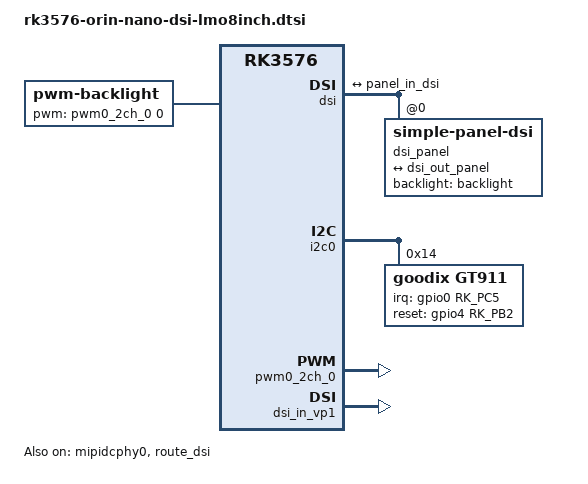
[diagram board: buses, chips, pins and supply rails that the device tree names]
// SPDX-License-Identifier: (GPL-2.0+ OR MIT)
/*
 * Guangzhou Easy EAl Technology Co., Ltd.
 *
 */

/{
	backlight: backlight {
		status = "okay";
		compatible = "pwm-backlight";
		pwms = <&pwm0_2ch_0 0 25000 0>;
		brightness-levels = <
			  0  20  20  21  21  22  22  23
			 23  24  24  25  25  26  26  27
			 27  28  28  29  29  30  30  31
			 31  32  32  33  33  34  34  35
			 35  36  36  37  37  38  38  39
			 40  41  42  43  44  45  46  47
			 48  49  50  51  52  53  54  55
			 56  57  58  59  60  61  62  63
			 64  65  66  67  68  69  70  71
			 72  73  74  75  76  77  78  79
			 80  81  82  83  84  85  86  87
			 88  89  90  91  92  93  94  95
			 96  97  98  99 100 101 102 103
			104 105 106 107 108 109 110 111
			112 113 114 115 116 117 118 119
			120 121 122 123 124 125 126 127
			128 129 130 131 132 133 134 135
			136 137 138 139 140 141 142 143
			144 145 146 147 148 149 150 151
			152 153 154 155 156 157 158 159
			160 161 162 163 164 165 166 167
			168 169 170 171 172 173 174 175
			176 177 178 179 180 181 182 183
			184 185 186 187 188 189 190 191
			192 193 194 195 196 197 198 199
			200 201 202 203 204 205 206 207
			208 209 210 211 212 213 214 215
			216 217 218 219 220 221 222 223
			224 225 226 227 228 229 230 231
			232 233 234 235 236 237 238 239
			240 241 242 243 244 245 246 247
			248 249 250 251 252 253 254 255
		>;
		default-brightness-level = <255>;
	};
};

&dsi {
	status = "okay";
	//rockchip,lane-rate = <1000>;
	dsi_panel: panel@0 {
		pinctrl-names = "default";
		pinctrl-0 = <&lcd_rst_gpio>;
		status = "okay";
		compatible = "simple-panel-dsi";
		reg = <0>;
		backlight = <&backlight>;
		dsi,flags = <(MIPI_DSI_MODE_VIDEO | MIPI_DSI_MODE_VIDEO_BURST |
			      MIPI_DSI_MODE_LPM | MIPI_DSI_MODE_NO_EOT_PACKET)>;
		dsi,format = <MIPI_DSI_FMT_RGB888>;
		dsi,lanes  = <4>;
		panel-init-sequence = [
			39 00 04 FF 98 81 03
			15 00 02 01 00
			15 00 02 02 00
			15 00 02 03 73
			15 00 02 04 00
			15 00 02 05 00
			15 00 02 06 08
			15 00 02 07 00
			15 00 02 08 00
			15 00 02 09 00
			15 00 02 0A 01
			15 00 02 0B 01
			15 00 02 0C 00
			15 00 02 0D 01
			15 00 02 0E 01
			15 00 02 0F 00
			15 00 02 10 00
			15 00 02 11 00
			15 00 02 12 00
			15 00 02 13 1F
			15 00 02 14 1F
			15 00 02 15 00
			15 00 02 16 00
			15 00 02 17 00
			15 00 02 18 00
			15 00 02 19 00
			15 00 02 1A 00
			15 00 02 1B 00
			15 00 02 1C 00
			15 00 02 1D 00
			15 00 02 1E 40
			15 00 02 1F C0
			15 00 02 20 06
			15 00 02 21 01
			15 00 02 22 06
			15 00 02 23 01
			15 00 02 24 88
			15 00 02 25 88
			15 00 02 26 00
			15 00 02 27 00
			15 00 02 28 3B
			15 00 02 29 03
			15 00 02 2A 00
			15 00 02 2B 00
			15 00 02 2C 00
			15 00 02 2D 00
			15 00 02 2E 00
			15 00 02 2F 00
			15 00 02 30 00
			15 00 02 31 00
			15 00 02 32 00
			15 00 02 33 00
			15 00 02 34 00
			15 00 02 35 00
			15 00 02 36 00
			15 00 02 37 00
			15 00 02 38 00
			15 00 02 39 00
			15 00 02 3A 00
			15 00 02 3B 00
			15 00 02 3C 00
			15 00 02 3D 00
			15 00 02 3E 00
			15 00 02 3F 00
			15 00 02 40 00
			15 00 02 41 00
			15 00 02 42 00
			15 00 02 43 00
			15 00 02 44 00
			15 00 02 50 01
			15 00 02 51 23
			15 00 02 52 45
			15 00 02 53 67
			15 00 02 54 89
			15 00 02 55 AB
			15 00 02 56 01
			15 00 02 57 23
			15 00 02 58 45
			15 00 02 59 67
			15 00 02 5A 89
			15 00 02 5B AB
			15 00 02 5C CD
			15 00 02 5D EF
			15 00 02 5E 00
			15 00 02 5F 01
			15 00 02 60 01
			15 00 02 61 06
			15 00 02 62 06
			15 00 02 63 07
			15 00 02 64 07
			15 00 02 65 00
			15 00 02 66 00
			15 00 02 67 02
			15 00 02 68 02
			15 00 02 69 05
			15 00 02 6A 05
			15 00 02 6B 02
			15 00 02 6C 0D
			15 00 02 6D 0D
			15 00 02 6E 0C
			15 00 02 6F 0C
			15 00 02 70 0F
			15 00 02 71 0F
			15 00 02 72 0E
			15 00 02 73 0E
			15 00 02 74 02
			15 00 02 75 01
			15 00 02 76 01
			15 00 02 77 06
			15 00 02 78 06
			15 00 02 79 07
			15 00 02 7A 07
			15 00 02 7B 00
			15 00 02 7C 00
			15 00 02 7D 02
			15 00 02 7E 02
			15 00 02 7F 05
			15 00 02 80 05
			15 00 02 81 02
			15 00 02 82 0D
			15 00 02 83 0D
			15 00 02 84 0C
			15 00 02 85 0C
			15 00 02 86 0F
			15 00 02 87 0F
			15 00 02 88 0E
			15 00 02 89 0E
			15 00 02 8A 02
			39 00 04 FF 98 81 04
			15 00 02 6C 15
			15 00 02 6E 2A
			15 00 02 6F 33
			15 00 02 8D 1B
			15 00 02 87 BA
			15 00 02 3A 24
			15 00 02 26 76
			15 00 02 B2 D1
			39 00 04 FF 98 81 01
			15 00 02 22 0A
			15 00 02 31 00                  
			15 00 02 43 66
			15 00 02 53 42
			15 00 02 50 87
			15 00 02 51 82
			15 00 02 60 15
			15 00 02 61 01
			15 00 02 62 0C
			15 00 02 63 00
			15 00 02 A0 00
			15 00 02 A1 13
			15 00 02 A2 23
			15 00 02 A3 14
			15 00 02 A4 16
			15 00 02 A5 29
			15 00 02 A6 1E
			15 00 02 A7 1D
			15 00 02 A8 86
			15 00 02 A9 1E
			15 00 02 AA 29
			15 00 02 AB 74
			15 00 02 AC 19
			15 00 02 AD 17
			15 00 02 AE 4B
			15 00 02 AF 20
			15 00 02 B0 26
			15 00 02 B1 4C
			15 00 02 B2 5D
			15 00 02 B3 3F
			15 00 02 C0 00
			15 00 02 C1 13
			15 00 02 C2 23
			15 00 02 C3 14
			15 00 02 C4 16
			15 00 02 C5 29
			15 00 02 C6 1E
			15 00 02 C7 1D
			15 00 02 C8 86
			15 00 02 C9 1E
			15 00 02 CA 29
			15 00 02 CB 74
			15 00 02 CC 19
			15 00 02 CD 17
			15 00 02 CE 4B
			15 00 02 CF 20
			15 00 02 D0 26
			15 00 02 D1 4C
			15 00 02 D2 5D
			15 00 02 D3 3F
			39 00 04 FF 98 81 00
			15 00 02 35 00
			05 78 01 11
			05 14 01 29
		];
		disp_timings0: display-timings {
			native-mode = <&dsi_timing0>;
			dsi_timing0: timing0 {
				clock-frequency = <68220000>;
				hactive = <800>;
				vactive = <1280>;
				hfront-porch = <20>;
				hsync-len = <20>;
				hback-porch = <20>;
				vfront-porch = <30>;
				vsync-len = <4>;
				vback-porch = <8>;
				hsync-active = <0>;
				vsync-active = <0>;
				de-active = <0>;
				pixelclk-active = <0>;
			};
		};

		ports {
			#address-cells = <1>;
			#size-cells = <0>;

			port@0 {
				reg = <0>;
				panel_in_dsi: endpoint {
					remote-endpoint = <&dsi_out_panel>;
				};
			};
		};
	};

	ports {
		#address-cells = <1>;
		#size-cells = <0>;

		port@1 {
			reg = <1>;
			dsi_out_panel: endpoint {
				remote-endpoint = <&panel_in_dsi>;
			};
		};
	};
};

/*
 * mipidcphy0 needs to be enabled
 * when dsi is enabled
 */
&mipidcphy0 {
	status = "okay";
};

&i2c0 {
	pinctrl-0 = <&i2c0m1_xfer>;
	status = "okay";

	gt911@14 {
		pinctrl-names = "default";
		pinctrl-0 = <&touch_gpio>;
		compatible = "goodix,gt911";
		reg = <0x14>;
		interrupt-parent = <&gpio0>;
		interrupts = <RK_PC5 0>;
		irq-gpios = <&gpio0 RK_PC5 0>;
		reset-gpios = <&gpio4 RK_PB2 0>;
	};
};

&pwm0_2ch_0 {
	status = "okay";
	pinctrl-0 = <&pwm0m0_ch0>;
};

&dsi_in_vp0 {
	status = "disabled";
};

&dsi_in_vp1 {
	status = "okay";
};

&dsi_in_vp2 {
	status = "disabled";
};

&dsi_in_vopl {
	status = "disabled";
};

&route_dsi {
	status = "okay";
	connect = <&vp1_out_dsi>;
};

&vp1 {
	assigned-clocks = <&cru DCLK_VP1_SRC>;
	assigned-clock-parents = <&cru PLL_VPLL>;
};


&pinctrl {
	lcd {
		lcd_rst_gpio: lcd-rst-gpio {
			rockchip,pins = <3 RK_PC6 RK_FUNC_GPIO &pcfg_output_high>;
		};
	};
	touch {
		touch_gpio: touch-gpio {
			rockchip,pins =
				<4 RK_PB2 RK_FUNC_GPIO &pcfg_pull_down>,
				<0 RK_PC5 RK_FUNC_GPIO &pcfg_pull_up>;
		};
	};
};

